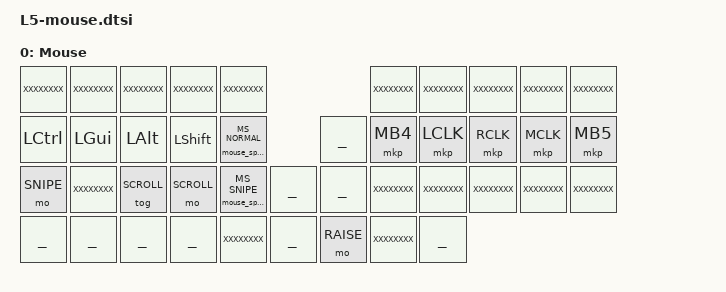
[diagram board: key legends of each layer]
/**
 * Held with the left outer thumb key. Laid out like the Charybdis 3x5 QMK mouse layer, for the
 * trackball: modifiers and buttons on the home row; the speed step (DPI_MOD) on G; Snipe, scroll
 * toggle, held scroll and the sniping speed step (S_D_MOD) on the bottom row.
 */

/ {
  keymap {
    compatible = "zmk,keymap";

	mouse_layer {
		label = "Mouse";
		bindings = <
	XXXXXXXX        XXXXXXXX        XXXXXXXX        XXXXXXXX        XXXXXXXX                                            XXXXXXXX        XXXXXXXX        XXXXXXXX        XXXXXXXX        XXXXXXXX
	&kp LCTRL       &kp LGUI        &kp LALT        &kp LSHFT       &mouse_speed MS_NORMAL                  ________        &mkp MB4        &mkp LCLK       &mkp RCLK       &mkp MCLK       &mkp MB5
	&mo SNIPE       XXXXXXXX        &tog SCROLL     &mo SCROLL      &mouse_speed MS_SNIPE ________            ________        XXXXXXXX        XXXXXXXX        XXXXXXXX        XXXXXXXX        XXXXXXXX
	________        ________        ________        ________        XXXXXXXX        ________            &mo RAISE       XXXXXXXX        ________
		>;
	};
  };
};
